# pse84 register map
Vendor: Infineon Technologies; Series: PSE84; File version: 1.0
CPU: CM33 r0p1, little endian, MPU, FPU, VTOR, 3 interrupt priority bits
Registers are 32-bit, read-write, reset 0x0 unless marked. A register's access mark holds for its fields unless they carry their own. Offsets are from the block's base; [hi:lo] are bit positions; lines under a group give offsets from that group; {n}, {i} and the like mark numbered series; 'fields as' and 'values as' point back to an identical list; <NAME> marks a mode.

## PTC — Programmable Threshold Comparator
Base 0x42E40000
0x400 STA group — PTC Static Configuration
  0x00 CFG — PTC Configuration Register (only accessible if ACTRLR.STATUS.MODE=0)
    [13:12] COMP1_OUT — See COMP0_OUT
      0=DISABLE (N/A); 1=RISING (N/A); 2=FALLING (N/A); 3=BOTH (N/A)
    [10] COMP1_HYST — See COMP0_HYST
    [9:8] COMP1_MODE — See COMP0_MODE
      0=OFF (N/A); 1=ULP (N/A); 2=LP (N/A); 3=NORMAL (N/A)
    [5:4] COMP0_OUT — Comparator 0 output (for interrupt and trigger generation)
      0=DISABLE (Disabled, no interrupts will be detected); 1=RISING (Rising edge); 2=FALLING (Falling edge); 3=BOTH (Both rising and falling edges)
    [2] COMP0_HYST — Add 30mV hysteresis to the comparator 0 0= Disable Hysteresis 1= Enable Hysteresis
    [1:0] COMP0_MODE — Operating mode for the comparator 0
      0=OFF; 1=ULP (Ultra lowpower operating mode (quiscent current < 300nA, 7us response time to 100mV overdrive). The comparator is biased using a local reference.); 2=LP (Low Power operating mode (quiscent current < 10uA, 1us response time to 100mV overdrive).); 3=NORMAL (Normal Power operating mode (quiscent current < 150uA, 0.1us response time to 100mV overdrive).)
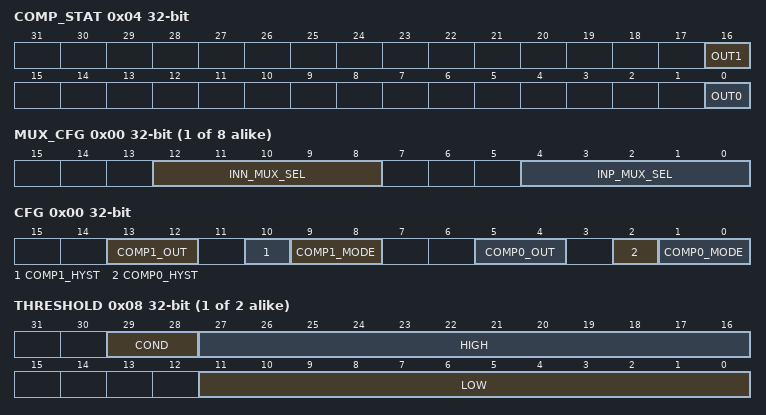
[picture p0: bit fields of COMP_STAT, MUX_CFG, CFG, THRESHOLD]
  0x04 COMP_STAT ro — PTC Status Register
    [16] OUT1 — Current output value of the comparator 1.
    [0] OUT0 — Current output value of the comparator 0.
  {0x8+4j} PP_CFG[{j}] (j=0..1) — Post Process Configuration register (only accessible if ACTRLR.STATUS.MODE=0)
    [1:0] INPUT_SEL
      0=DISABLED (N/A); 1=COMP0 (Comparator 0 output); 2=COMP1 (Comparator 1 output); 3=RSVD (N/A)
{0x600+0x10*i} DYN[{i}] (i=0..7) group — PTC Dynamic Configuration (only accessible if ACTRLR.STATUS.MODE=0)
  0x00 MUX_CFG — PTC Mux Configuration
    [12:8] INN_MUX_SEL
      0=COREIO_0 (CTBL0 GPIO Pin 1. See product datasheet for specific pin number.); 1=COREIO_1 (CTBL0 GPIO Pin 4. See product datasheet for specific pin number.); 2=COREIO_2 (CTBL0 GPIO Pin 6. See product datasheet for specific pin number.); 3=COREIO_3 (CTBL0 GPIO Pin 7. See product datasheet for specific pin number.); 4=COREIO_4 (CTBL1 GPIO Pin 1. See product datasheet for specific pin number.); 5=COREIO_5 (CTBL1 GPIO Pin 4. See product datasheet for specific pin number.); 6=COREIO_6 (CTBL1 GPIO Pin 6. See product datasheet for specific pin number.); 7=COREIO_7 (CTBL1 GPIO Pin 7. See product datasheet for specific pin number.); 8=CTBL0_OA0 (CTBL0 Opamp0 Output); 9=CTBL0_OA1 (CTBL0 Opamp1 Output); 10=CTBL1_OA0 (CTBL1 Opamp0 Output); 11=CTBL1_OA1 (CTBL1 Opamp1 Output); 12=VREF0 (DAC0 output); 13=VREF1 (DAC1 output); 14=VREF2 (PRB VREF0 output); 15=VREF3 (PRB VREF1 output); {v}=GPIO_{v-16} (SAR/PTC GPIO Pin {v-16}. See product datasheet for specific pin number.) (v=16..23); {v}=RESEREVED_{v-24} (N/A) (v=24..31)
    [4:0] INP_MUX_SEL
      values as INN_MUX_SEL
{0x700+0x10*i} PP[{i}] (i=0..1) group — PTC Post Process (only accessible if ACTRLR.STATUS.MODE=0)
  0x00 CFG — Post Processing configuration
    [11:8] LUT — LUT function A and B corresponds to the individual post processor range outputs (i.e. for PTC_PP_STRUCT0_CFG.LUT, A is the Post Processor 0 range comparison, and B is the Post Processor 1 range comparison. For PTC_PP_STRUCT1_CFG.LUT, A is the Post Processor 1 range comparison, and B is the Post Processor 0 range comparison)
      0=A (N/A); 1=A_BAR_AND_B (N/A); 2=B (N/A); 3=A_AND_B (N/A); 4=A_AND_B_BAR (N/A); 5=A_XOR_B (N/A); 6=A_OR_B (N/A); 7=A_NOR_B (N/A); 8=A_XNOR_B (N/A); 9=B_BAR (N/A); 10=A_OR_B_BAR (N/A); 11=A_BAR (N/A); 12=A_BAR_OR_B (N/A); 13=A_NAND_B (N/A); 14=RSVD0 (N/A); 15=RSVD1 (N/A)
    [3:2] MODE — Post Processor Counter Mode
      0=DIRECT (Direct mode: in this mode, the counter is configured to count the number of INPUT_TYPES. The condition is evaluated (based on the THRESHOLD register) every rising edge of the post precessor clock. If the condition is met, the counter is reset.); 1=FRAME (Frame mode: in this mode, the counter is configured to count the number of INPUT_TYPES that occur during a given frame. The frame rate is determined by FRAME.PERIOD. At the end of the frame, the condition is evaluated (based on the THRESHOLD register) and the counter is reset to begin the next frame.); 2=WINDOW (Window mode: in this mode, the counter is configured to count the number of INPUT_TYPES that occur inside a given window. The window size is set by WINDOW.SIZE. After filling the window, the condition is evaluted (based on the THRESHOLD register) every rising edge of the post processor clock. The counter is not reset in this mode.); 3=RSVD (N/A)
    [1:0] INPUT_TYPE — Input data type (selected by PTC_STA_CFG.PP_CFG0(1).INPUT_SEL. )
      0=LEVEL (level sensitive); 1=EDGE_RISING (rising edge sensitive); 2=EDGE_FALLING (falling edge sensitive); 3=EDGE_BOTH (both rising and falling edge sensitive)
  0x04 FRAME — Post Processing frame
    [11:0] PERIOD — Period Value. This field is only applicable if CFG.MODE=FRAM. The frame rate is PERIOD+1 PTC Clock cycles.
  0x08 THRESHOLD — Post Processing threshold
    [29:28] COND — Range condition select.
      0=BELOW (counter output < LOW); 1=INSIDE (LOW <= counter output < HIGH); 2=ABOVE (counter output > HIGH); 3=OUTSIDE (counter output < LOW || counter output >= HIGH)
    [27:16] HIGH — High threshold
    [11:0] LOW — Low threshold
  0x0C WINDOW reset 0x4 — Post Processing window
    [2:0] SIZE — Window size. This field is only applicable if CFG.MODE=WINDOW
      0=WINDOW_TWO (Window size of 2); 1=WINDOW_FOUR (Window size of 4); 2=WINDOW_EIGHT (Window size of 8); 3=WINDOW_SIXTEEN (Window size of 16); 4=WINDOW_THIRTY_TWO (Window size of 32); 5=WINDOW_SIXTY_FOUR (Window size of 64); 6=WINDOW_ONE_TWENTY_EIGHT (Window size of 128); 7=RSVD (N/A)
0xF00 TRIM group — PTC Trim registers (only accessible if ACTRLR.STATUS.MODE=0)
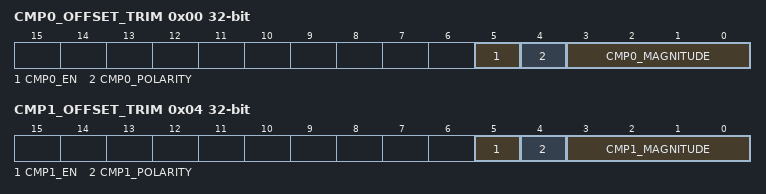
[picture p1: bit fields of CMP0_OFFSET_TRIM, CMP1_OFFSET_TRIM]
  0x00 CMP0_OFFSET_TRIM — Comparator 0 offset trim register
    [5] CMP0_EN — enables CMP0 offset trim 0 = disabled 1 = enabled
    [4] CMP0_POLARITY — polarity of CMP0 offset trim. 0 = negative 1 = positive
    [3:0] CMP0_MAGNITUDE — magnitude of CMP0 offset trim. 1mV offset shift per bit.
  0x04 CMP1_OFFSET_TRIM — Comparator 1 offset trim register
    [5] CMP1_EN — enables CMP1 offset trim 0 = disabled 1 = enabled
    [4] CMP1_POLARITY — polarity of CMP1 offset trim. 0 = negative 1 = positive
    [3:0] CMP1_MAGNITUDE — magnitude of CMP1 offset trim. 1mV offset shift per bit.
